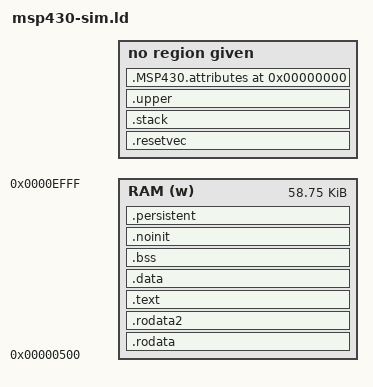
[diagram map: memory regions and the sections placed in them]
/* Copyright (c) 2013-2015 Red Hat, Inc. All rights reserved.

   This copyrighted material is made available to anyone wishing to use, modify,
   copy, or redistribute it subject to the terms and conditions of the BSD
   License.   This program is distributed in the hope that it will be useful,
   but WITHOUT ANY WARRANTY expressed or implied, including the implied warranties
   of MERCHANTABILITY or FITNESS FOR A PARTICULAR PURPOSE.  A copy of this license
   is available at http://www.opensource.org/licenses. Any Red Hat trademarks that
   are incorporated in the source code or documentation are not subject to the BSD
   License and may only be used or replicated with the express permission of
   Red Hat, Inc.  */

/* Default linker script, for normal MSP430 executables.  */

OUTPUT_ARCH(msp430)
ENTRY(_start)

INCLUDE intr_vectors.ld

MEMORY
{
  RAM (w) : ORIGIN = 0x00500, LENGTH = 0x0eb00
}

SECTIONS
{
  .resetvec :
  {
    *(.resetvec)
  } > VECT31

  .rodata :
  {
    . = ALIGN(2);
    *(.plt)
    . = ALIGN(2);
    *(.lower.rodata.* .lower.rodata)
    . = ALIGN(2);
    *(.rodata .rodata.* .gnu.linkonce.r.* .const .const:*)
    . = ALIGN(2);
    *(.either.rodata.* .either.rodata)
    . = ALIGN(2);
    *(.rodata1)

    KEEP (*(.gcc_except_table)) *(.gcc_except_table.*)
    PROVIDE (__preinit_array_start = .);
    KEEP (*(.preinit_array))
    PROVIDE (__preinit_array_end = .);
    PROVIDE (__init_array_start = .);
    KEEP (*(SORT(.init_array.*)))
    KEEP (*(.init_array))
    PROVIDE (__init_array_end = .);
    PROVIDE (__fini_array_start = .);
    KEEP (*(.fini_array))
    KEEP (*(SORT(.fini_array.*)))
    PROVIDE (__fini_array_end = .);

  } > RAM

  /* Note: This is a separate .rodata section for sections which are
     read only but which older linkers treat as read-write.
     This prevents older linkers from marking the entire .rodata
     section as read-write.  */
  .rodata2 :
  {
    . = ALIGN(2);
    *(.eh_frame_hdr)
    KEEP (*(.eh_frame))

    /* gcc uses crtbegin.o to find the start of the constructors, so
       we make sure it is first.  Because this is a wildcard, it
       doesn't matter if the user does not actually link against
       crtbegin.o; the linker won't look for a file to match a
       wildcard.  The wildcard also means that it doesn't matter which
       directory crtbegin.o is in.  */
    KEEP (*crtbegin*.o(.ctors))

    /* We don't want to include the .ctor section from from the
       crtend.o file until after the sorted ctors.  The .ctor section
       from the crtend file contains the end of ctors marker and it
       must be last */
    KEEP (*(EXCLUDE_FILE (*crtend*.o ) .ctors))
    KEEP (*(SORT(.ctors.*)))
    KEEP (*(.ctors))

    KEEP (*crtbegin*.o(.dtors))
    KEEP (*(EXCLUDE_FILE (*crtend*.o ) .dtors))
    KEEP (*(SORT(.dtors.*)))
    KEEP (*(.dtors))
  } > RAM

  .text :
  {
    . = ALIGN(2);
    PROVIDE (_start = .);
    KEEP (*(SORT(.crt_*)))
    *(.lowtext)
    *(.lower.text.* .lower.text)
    *(.text .stub .text.* .gnu.linkonce.t.* .text:*)
    *(.either.text.* .either.text)
    KEEP (*(.text.*personality*))
    /* .gnu.warning sections are handled specially by elf32.em.  */
    *(.gnu.warning)
    *(.interp .hash .dynsym .dynstr .gnu.version*)
    PROVIDE (__etext = .);
    PROVIDE (_etext = .);
    PROVIDE (etext = .);
    . = ALIGN(2);
    KEEP (*(.tm_clone_table))
  } > RAM

  .data :
  {
    . = ALIGN(2);
    PROVIDE (__datastart = .);

    *(.lower.data.* .lower.data)

    *(.data .data.* .gnu.linkonce.d.*)

    *(.either.data.* .either.data)

    KEEP (*(.jcr))
    *(.data.rel.ro.local) *(.data.rel.ro*)
    *(.dynamic)

    KEEP (*(.gnu.linkonce.d.*personality*))
    SORT(CONSTRUCTORS)
    *(.data1)
    *(.got.plt) *(.got)

    /* We want the small data sections together, so single-instruction offsets
       can access them all, and initialized data all before uninitialized, so
       we can shorten the on-disk segment size.  */
    . = ALIGN(2);
    *(.sdata .sdata.* .gnu.linkonce.s.* D_2 D_1)

    . = ALIGN(2);
    _edata = .;
    PROVIDE (edata = .);
    PROVIDE (__dataend = .);
  } > RAM

  /* Note that crt0 assumes this is a multiple of two; all the
     start/stop symbols are also assumed word-aligned.  */
  PROVIDE(__romdatastart = LOADADDR(.data));
  PROVIDE (__romdatacopysize = SIZEOF(.data));

  .bss :
  {
    . = ALIGN(2);
    PROVIDE (__bssstart = .);
    *(.lower.bss.* .lower.bss)
    *(.dynbss)
    *(.sbss .sbss.*)
    *(.bss .bss.* .gnu.linkonce.b.*)
    *(.either.bss.* .either.bss)
    . = ALIGN(2);
    *(COMMON)
    . = ALIGN(2);
    PROVIDE (__bssend = .);
  } > RAM
  PROVIDE (__bsssize = SIZEOF(.bss));

  /* This section contains data that is not initialised during load
     *or* application reset.  */
  .noinit (NOLOAD) :
  {
    . = ALIGN(2);
    PROVIDE (__noinit_start = .);
    *(.noinit)
    . = ALIGN(2);
    PROVIDE (__noinit_end = .);
  } > RAM

  /* This section is intended to contain data that *is* initialised during load
     but *not* on application reset.  Normally the section would be stored in
     FLASH RAM, but this is not available here.  We just have to hope that the
     programmer knows what they are doing.  */
  .persistent :
  {
    . = ALIGN(2);
    PROVIDE (__persistent_start = .);
    *(.persistent)
    . = ALIGN(2);
    PROVIDE (__persistent_end = .);
  } > RAM
 
  _end = .;
  PROVIDE (end = .);

  /* The __stack_size value of 0x100 is just a guess, but since it is
     PROVIDEd the user can override it on the command line.  It has to be
     set here, rather than inside the .stack section, as symbols defined
     inside sections are only evaluated during the final phase of the link,
     long after the ASSERT is checked.  An ASSERT referencing a PROVIDED but
     not yet evaluated symbol will automatically fail.

     FIXME: It would be nice if this value could be automatically set via
     gcc's -fstack-usage command line option somehow.  */
  PROVIDE (__stack_size = 0x100);

  .stack (ORIGIN (RAM) + LENGTH(RAM)) :
  {
    PROVIDE (__stack = .);
    *(.stack)

    /* Linker section checking ignores empty sections like
       this one so we have to have our own test here.  */
    /* FIXME: This test is triggering erroneously.  I have not figured
       out why yet, but I am disabling it for now as it prevents the
       gcc testsuite from working.  */
    /* ASSERT (__stack > (_end + __stack_size),
            "Error: Too much data - no room left for the stack"); */
  }

  /* Make sure that .upper sections are not used without -mlarge support.  */
  .upper :
  {
    *(.upper.rodata.* .upper.rodata)
    *(.upper.data.* .upper.data)
    *(.upper.bss.* .upper.bss)
    *(.upper.text.* .upper.text)  
    ASSERT (SIZEOF(.upper) == 0, "This MCU does not support high memory");
  }

  /* The rest are all not normally part of the runtime image.  */

  .MSP430.attributes 0 :
  {
    KEEP (*(.MSP430.attributes))
    KEEP (*(.gnu.attributes))
    KEEP (*(__TI_build_attributes))
  }

  /* Stabs debugging sections.  */
  .stab          0 : { *(.stab) }
  .stabstr       0 : { *(.stabstr) }
  .stab.excl     0 : { *(.stab.excl) }
  .stab.exclstr  0 : { *(.stab.exclstr) }
  .stab.index    0 : { *(.stab.index) }
  .stab.indexstr 0 : { *(.stab.indexstr) }
  .comment       0 : { *(.comment) }
  /* DWARF debug sections.
     Symbols in the DWARF debugging sections are relative to the beginning
     of the section so we begin them at 0.  */
  /* DWARF 1.  */
  .debug          0 : { *(.debug) }
  .line           0 : { *(.line) }
  /* GNU DWARF 1 extensions.  */
  .debug_srcinfo  0 : { *(.debug_srcinfo) }
  .debug_sfnames  0 : { *(.debug_sfnames) }
  /* DWARF 1.1 and DWARF 2.  */
  .debug_aranges  0 : { *(.debug_aranges) }
  .debug_pubnames 0 : { *(.debug_pubnames) }
  /* DWARF 2 */
  .debug_info     0 : { *(.debug_info .gnu.linkonce.wi.*) }
  .debug_abbrev   0 : { *(.debug_abbrev) }
  .debug_line     0 : { *(.debug_line .debug_line.* .debug_line_end ) }
  .debug_frame    0 : { *(.debug_frame) }
  .debug_str      0 : { *(.debug_str) }
  .debug_loc      0 : { *(.debug_loc) }
  .debug_macinfo  0 : { *(.debug_macinfo) }
  /* SGI/MIPS DWARF 2 extensions.  */
  .debug_weaknames 0 : { *(.debug_weaknames) }
  .debug_funcnames 0 : { *(.debug_funcnames) }
  .debug_typenames 0 : { *(.debug_typenames) }
  .debug_varnames  0 : { *(.debug_varnames) }
  /* DWARF 3.  */
  .debug_pubtypes 0 : { *(.debug_pubtypes) }
  .debug_ranges   0 : { *(.debug_ranges) }
  /* DWARF Extension.  */
  .debug_macro    0 : { *(.debug_macro) }

  /DISCARD/ : { *(.note.GNU-stack) }
}
